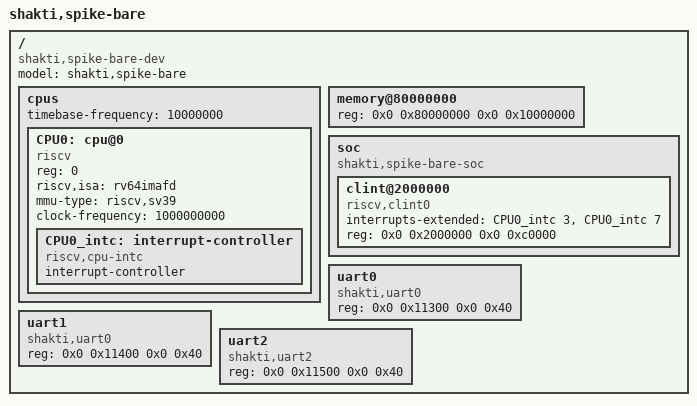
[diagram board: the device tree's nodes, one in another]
/***************************************************************************
* Project           			:  shakti devt board
* Name of the file	     		:  design.dts
* Brief Description of file             :  dts for aardonyx.
* Name of Author    	                :  Sathya
* Email ID                              :  sathya281@gmail.com

    Copyright (C) 2019  IIT Madras. All rights reserved.

    This program is free software: you can redistribute it and/or modify
    it under the terms of the GNU General Public License as published by
    the Free Software Foundation, either version 3 of the License, or
    (at your option) any later version.

    This program is distributed in the hope that it will be useful,
    but WITHOUT ANY WARRANTY; without even the implied warranty of
    MERCHANTABILITY or FITNESS FOR A PARTICULAR PURPOSE.  See the
    GNU General Public License for more details.

    You should have received a copy of the GNU General Public License
    along with this program.  If not, see <https://www.gnu.org/licenses/>.

***************************************************************************/

/dts-v1/;

/ {
  #address-cells = <2>;
  #size-cells = <2>;
  compatible = "shakti,spike-bare-dev";
  model = "shakti,spike-bare";
  cpus {
    #address-cells = <1>;
    #size-cells = <0>;
    timebase-frequency = <10000000>;
    CPU0: cpu@0 {
      device_type = "cpu";
      reg = <0>;
      status = "okay";
      compatible = "riscv";
      riscv,isa = "rv64imafd";
      mmu-type = "riscv,sv39";
      clock-frequency = <1000000000>;
      CPU0_intc: interrupt-controller {
        #interrupt-cells = <1>;
        interrupt-controller;
        compatible = "riscv,cpu-intc";
      };
    };
  };
  memory@80000000 {
    device_type = "memory";
    reg = <0x0 0x80000000 0x0 0x10000000 >;
  };
  soc {
    #address-cells = <2>;
    #size-cells = <2>;
    compatible = "shakti,spike-bare-soc", "simple-bus";
    ranges;
    clint@2000000 {
      compatible = "riscv,clint0";
      interrupts-extended = <&CPU0_intc 3 &CPU0_intc 7 >;
      reg = <0x0 0x2000000 0x0 0xc0000>;
    };
  };
 uart0 {
  compatible = "shakti,uart0";
  reg= <0x0 0x11300 0x0 0x40>;
 };
 uart1 {
  compatible = "shakti,uart0";
  reg= <0x0 0x11400 0x0 0x40>;
 };
 uart2 {
  compatible = "shakti,uart2";
  reg= <0x0 0x11500 0x0 0x40>;
 };
};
